# CY8C5868AXI_LP035 register map
File version: 0.1
CY8C58LP
Registers are 8-bit, read-write, no defined reset value unless marked. A register's access mark holds for its fields unless they carry their own. Offsets are from the block's base; lines under a group give offsets from that group; [hi:lo] are bit positions; {n}, {i} and the like mark numbered series; 'fields as' and 'values as' point back to an identical list; <NAME> marks a mode.

## Memory map
0x400043AA ADC_DelSig_1 size 0x17E0
0x40006408 Echo_Timer size 0x172
0x40006466 EOC_SR size 0x31
0x40006474 FanController size 0x103
0x40006508 Trigger_Timer size 0x94

## Trigger_Timer
Base 0x40006508
0x00 Trigger_Timer_COUNTER 32-bit — UDB.A0 - Current Down Counter Value
0x20 Trigger_Timer_PERIOD 32-bit — UDB.D0 - Assigned Period
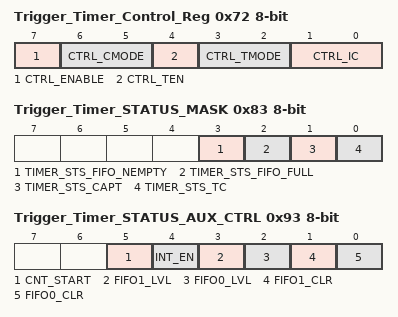
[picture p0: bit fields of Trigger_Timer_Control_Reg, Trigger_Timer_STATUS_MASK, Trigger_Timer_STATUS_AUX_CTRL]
0x72 Trigger_Timer_Control_Reg — UDB Control Register - Assigned Control Register Value
  [7] CTRL_ENABLE — Enable the Timer
  [6:5] CTRL_CMODE — Capture Mode
  [4] CTRL_TEN — Trigger Enable Bit
  [3:2] CTRL_TMODE — Trigger Mode
  [1:0] CTRL_IC — Interrupt Count
0x83 Trigger_Timer_STATUS_MASK — UDB Status bits Interrupt Mask Enable Register
  [3] TIMER_STS_FIFO_NEMPTY ro — FIFO Empty status
  [2] TIMER_STS_FIFO_FULL ro — FIFO Full Status
  [1] TIMER_STS_CAPT ro — Enables the Interrupt on Capture
  [0] TIMER_STS_TC ro — Enables the Interrupt on TC
0x93 Trigger_Timer_STATUS_AUX_CTRL — UDB Auxilliary Control Register
  [5] CNT_START — FIFO0 clear
    0=E_CNT_START0 (Disable counter); 1=E_CNT_START1 (Enable counter)
  [4] INT_EN
    0=E_INT_EN0 (Interrupt disabled); 1=E_INT_EN1 (Interrupt enabled)
  [3] FIFO1_LVL — FIFO level
    0=E_FIFO_LVL_0 (FIFO LVL: input mode: FIFO not full; output mode: FIFO not empty); 1=E_FIFO_LVL_1 (FIFO LVL: input mode: FIFO at least 1/2 empty; output mode: FIFO at least 1/2 full)
  [2] FIFO0_LVL — FIFO level
    values as FIFO1_LVL
  [1] FIFO1_CLR — FIFO1 clear
    0=E_FIFO_CLR_0 (Normal FIFO operation); 1=E_FIFO_CLR_1 (Clear FIFO state)
  [0] FIFO0_CLR — FIFO0 clear
    values as FIFO1_CLR

## Echo_Timer
Base 0x40006408
0x00 Echo_Timer_COUNTER 16-bit — UDB.A0 - Current Down Counter Value
0x20 Echo_Timer_PERIOD 16-bit — UDB.D0 - Assigned Period
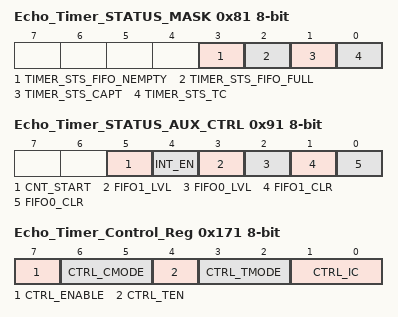
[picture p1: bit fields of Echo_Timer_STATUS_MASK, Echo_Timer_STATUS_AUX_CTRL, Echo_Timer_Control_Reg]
0x81 Echo_Timer_STATUS_MASK — UDB Status bits Interrupt Mask Enable Register
  [3] TIMER_STS_FIFO_NEMPTY ro — FIFO Empty status
  [2] TIMER_STS_FIFO_FULL ro — FIFO Full Status
  [1] TIMER_STS_CAPT ro — Enables the Interrupt on Capture
  [0] TIMER_STS_TC ro — Enables the Interrupt on TC
0x91 Echo_Timer_STATUS_AUX_CTRL — UDB Auxilliary Control Register
  [5] CNT_START — FIFO0 clear
    0=E_CNT_START0 (Disable counter); 1=E_CNT_START1 (Enable counter)
  [4] INT_EN
    0=E_INT_EN0 (Interrupt disabled); 1=E_INT_EN1 (Interrupt enabled)
  [3] FIFO1_LVL — FIFO level
    0=E_FIFO_LVL_0 (FIFO LVL: input mode: FIFO not full; output mode: FIFO not empty); 1=E_FIFO_LVL_1 (FIFO LVL: input mode: FIFO at least 1/2 empty; output mode: FIFO at least 1/2 full)
  [2] FIFO0_LVL — FIFO level
    values as FIFO1_LVL
  [1] FIFO1_CLR — FIFO1 clear
    0=E_FIFO_CLR_0 (Normal FIFO operation); 1=E_FIFO_CLR_1 (Clear FIFO state)
  [0] FIFO0_CLR — FIFO0 clear
    values as FIFO1_CLR
0x171 Echo_Timer_Control_Reg — UDB Control Register - Assigned Control Register Value
  [7] CTRL_ENABLE — Enable the Timer
  [6:5] CTRL_CMODE — Capture Mode
  [4] CTRL_TEN — Trigger Enable Bit
  [3:2] CTRL_TMODE — Trigger Mode
  [1:0] CTRL_IC — Interrupt Count

## FanController
Base 0x40006474
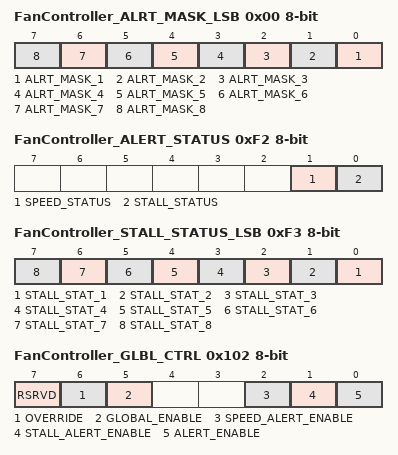
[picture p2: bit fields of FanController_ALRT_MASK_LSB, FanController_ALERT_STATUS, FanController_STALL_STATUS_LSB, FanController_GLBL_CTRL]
0x00 FanController_ALRT_MASK_LSB — Alert Mask LSB Register
  [n-1] ALRT_MASK_{n} (n=1..8) — Alert Mask for Fan{n}
0xF2 FanController_ALERT_STATUS — Alert Status Register
  [1] SPEED_STATUS ro — Speed status for all Fans
    0=NO_SPEED_ERROR (No speed error occurred); 1=SPEED_ERROR (Speed error is occurred)
  [0] STALL_STATUS ro — Stall status for all Fans
    0=NO_STALL (No stall occurred); 1=STALL (Stall is occurred)
0xF3 FanController_STALL_STATUS_LSB — Stall Status LSB Register
  [n-1] STALL_STAT_{n} (n=1..8) — Stall status for Fan{n}
0x102 FanController_GLBL_CTRL — Global Control Register
  [7] RSRVD ro — Reserved
  [6] OVERRIDE — HW mode override bit
    0=OVRD_DISABLED (HW control not overrided); 1=OVRD_ENABLED (HW control overrided)
  [5] GLOBAL_ENABLE — Global enable signal for the component
    0=COMP_DISABLED (Component disabled); 1=COMP_ENABLED (Component is enabled)
  [2] SPEED_ALERT_ENABLE — Speed alert enable signal
    0=SPEED_ALRT_DIS (Generation of speed alert is disabled); 1=SPEED_ALRT_EN (Generation of speed alert is enabled)
  [1] STALL_ALERT_ENABLE — Stall alert enable signal
    0=STALL_ALRT_DIS (Generation of stall alert is disabled); 1=STALL_ALRT_EN (Generation of stall alert is enabled)
  [0] ALERT_ENABLE — Global alert enable signal
    0=ALERTS_DIS (Generation of all alerts is disabled); 1=ALERTS_EN (Generation of alerts is enabled)
